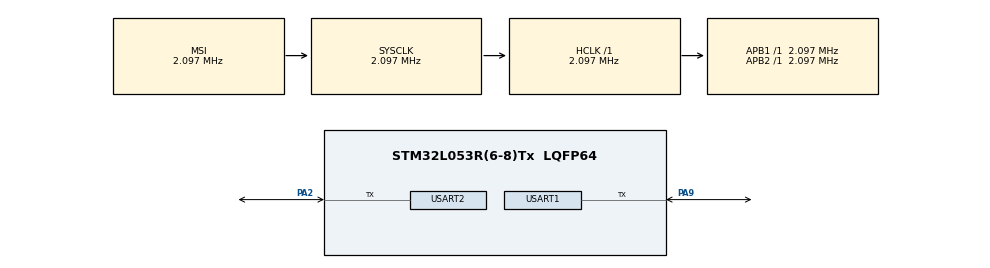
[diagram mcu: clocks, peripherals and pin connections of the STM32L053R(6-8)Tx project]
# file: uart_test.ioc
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Dma.Request0=USART1_TX
Dma.USART1_TX.0.Direction=DMA_MEMORY_TO_PERIPH
Dma.USART1_TX.0.Instance=DMA1_Channel2
Dma.USART1_TX.0.MemDataAlignment=DMA_MDATAALIGN_BYTE
Dma.USART1_TX.0.MemInc=DMA_MINC_ENABLE
Dma.USART1_TX.0.Mode=DMA_NORMAL
Dma.USART1_TX.0.PeriphDataAlignment=DMA_PDATAALIGN_BYTE
Dma.USART1_TX.0.PeriphInc=DMA_PINC_DISABLE
Dma.USART1_TX.0.Priority=DMA_PRIORITY_LOW
Mcu.Family=STM32L0
Mcu.Name=STM32L053R(6-8)Tx
Mcu.Package=LQFP64
NVIC.DMA1_Channel2_3_IRQn=true\:0\:0\:false\:false\:true
NVIC.USART1_IRQn=true\:0\:0\:false\:false\:true
PA2.Mode=Half_duplex(single_wire_mode)
PA2.Signal=USART2_TX
PA9.Mode=Half_duplex(single_wire_mode)
PA9.Signal=USART1_TX
ProjectManager.HeapSize=0x200
ProjectManager.StackSize=0x400
ProjectManager.TargetToolchain=SW4STM32
RCC.48MEnable=false
RCC.ADCEnable=false
RCC.AHBFreq_Value=2097000
RCC.APB1Freq_Value=2097000
RCC.APB1TimFreq_Value=2097000
RCC.APB2Freq_Value=2097000
RCC.APB2TimFreq_Value=2097000
RCC.ClockTypeHCLK=RCC_CLOCKTYPE_HCLK
RCC.ClockTypePCLK1=RCC_CLOCKTYPE_PCLK1
RCC.ClockTypePCLK2=RCC_CLOCKTYPE_PCLK2
RCC.ClockTypeSysClk=RCC_CLOCKTYPE_SYSCLK
RCC.EnableCSSLSE=false
RCC.EnableHSE=false
RCC.EnableHSELCDDevisor=false
RCC.EnableHSERTCDevisor=false
RCC.EnableLSE=false
RCC.EnableLSERTC=false
RCC.EnbaleCSS=false
RCC.HSE_VALUE=8000000
RCC.HSI16State=RCC_HSI_OFF
RCC.HSI16_VALUE=16000000
RCC.HSI48State=RCC_HSI48_OFF
RCC.HSI48_VALUE=48000000
RCC.HSI_VALUE=16000000
RCC.I2C1Enable=false
RCC.IWDGEnable=false
RCC.LCDEnable=false
RCC.LPTIMEnable=false
RCC.LPUARTEnable=false
RCC.LSE_VALUE=32768
RCC.LSIState=RCC_LSI_OFF
RCC.MCOEnable=false
RCC.MSI_VALUE=2097000
RCC.PLLSource=RCC_PLLSOURCE_HSI
RCC.PLLSourceVirtual=RCC_PLLSOURCE_HSI
RCC.PLLState=RCC_PLL_OFF
RCC.RCC_PERIPHCLK_USART1Var=RCC_PERIPHCLK_USART1
RCC.RCC_PERIPHCLK_USART2Var=RCC_PERIPHCLK_USART2
RCC.RNGEnable=false
RCC.RTCEnable=false
RCC.SYSCLKFreq_VALUE=2097000
RCC.USART1Enable=true
RCC.USART2Enable=true
RCC.USBEnable=false
RCC.VCOOutputFreq_Value=48000000
USART1.BaudRate=115200
USART1.OverrunDisableParam=UART_ADVFEATURE_OVERRUN_DISABLE
USART1.VirtualMode-Half_duplex(single_wire_mode)=VM_ASYNC
USART1.WordLength=WORDLENGTH_8B
USART2.VirtualMode-Half_duplex(single_wire_mode)=VM_ASYNC
board=uart_test

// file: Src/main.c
/**
  ******************************************************************************
  * File Name          : main.c
  * Description        : Main program body
  ******************************************************************************
  *
  * COPYRIGHT(c) 2017 STMicroelectronics
  *
  * Redistribution and use in source and binary forms, with or without modification,
  * are permitted provided that the following conditions are met:
  *   1. Redistributions of source code must retain the above copyright notice,
  *      this list of conditions and the following disclaimer.
  *   2. Redistributions in binary form must reproduce the above copyright notice,
  *      this list of conditions and the following disclaimer in the documentation
  *      and/or other materials provided with the distribution.
  *   3. Neither the name of STMicroelectronics nor the names of its contributors
  *      may be used to endorse or promote products derived from this software
  *      without specific prior written permission.
  *
  * THIS SOFTWARE IS PROVIDED BY THE COPYRIGHT HOLDERS AND CONTRIBUTORS "AS IS"
  * AND ANY EXPRESS OR IMPLIED WARRANTIES, INCLUDING, BUT NOT LIMITED TO, THE
  * IMPLIED WARRANTIES OF MERCHANTABILITY AND FITNESS FOR A PARTICULAR PURPOSE ARE
  * DISCLAIMED. IN NO EVENT SHALL THE COPYRIGHT HOLDER OR CONTRIBUTORS BE LIABLE
  * FOR ANY DIRECT, INDIRECT, INCIDENTAL, SPECIAL, EXEMPLARY, OR CONSEQUENTIAL
  * DAMAGES (INCLUDING, BUT NOT LIMITED TO, PROCUREMENT OF SUBSTITUTE GOODS OR
  * SERVICES; LOSS OF USE, DATA, OR PROFITS; OR BUSINESS INTERRUPTION) HOWEVER
  * CAUSED AND ON ANY THEORY OF LIABILITY, WHETHER IN CONTRACT, STRICT LIABILITY,
  * OR TORT (INCLUDING NEGLIGENCE OR OTHERWISE) ARISING IN ANY WAY OUT OF THE USE
  * OF THIS SOFTWARE, EVEN IF ADVISED OF THE POSSIBILITY OF SUCH DAMAGE.
  *
  ******************************************************************************
  */
#include "main.h"
#include "stm32l0xx_hal.h"

/* USER CODE BEGIN Includes */
#include "OwCompleteSearch.h"
#include "Callback.h"
#include "OneWireio.h"
#include "Search.h"
#include "OwVariable.h"
#include <stdlib.h>
/* USER CODE END Includes */

UART_HandleTypeDef huart1;
UART_HandleTypeDef huart2;
DMA_HandleTypeDef hdma_usart1_tx;

/* USER CODE BEGIN PV */
/* Private variables ---------------------------------------------------------*/
uint8_t send1 = 0xff;
uint8_t send0 = 0;
uint8_t uartRx;
uint8_t uartTempRx;
uint8_t pData;
uint8_t pDataTR[2] = {0xf0, 0x22};
int callBEn = 0;
uint8_t *romUIDprivate;
/* USER CODE END PV */

void SystemClock_Config(void);
void Error_Handler(void);
static void MX_GPIO_Init(void);
static void MX_DMA_Init(void);
static void MX_USART1_UART_Init(void);
static void MX_USART2_UART_Init(void);

/* USER CODE BEGIN PFP */
/* Private function prototypes -----------------------------------------------*/
HAL_StatusTypeDef HAL_HalfDuplex_EnableTxRx(UART_HandleTypeDef *huart);
/* USER CODE END PFP */

int main(void)
{

  /* MCU Configuration----------------------------------------------------------*/

  /* Reset of all peripherals, Initializes the Flash interface and the Systick. */
  HAL_Init();

  /* Configure the system clock */
  SystemClock_Config();

  /* Initialize all configured peripherals */
  MX_GPIO_Init();
  MX_DMA_Init();
  MX_USART1_UART_Init();
  MX_USART2_UART_Init();

  /* USER CODE BEGIN 2 */
  HAL_HalfDuplex_EnableTxRx(&huart1);
  owRomSearchInit();
  /* USER CODE END 2 */

  /* Infinite loop */
  while (1)
  {

  /* USER CODE BEGIN 3 */

    //callback flag is set to generate evt to send back to func in callbackList
	  if(callBEn){
		  Event evt;
		  evt.evtType = UART_RX_SUCCESS;
		  TxRxCpltEvData evData;
		  evData.uartRxVal = uartRxDataBuffer;
		  evt.data = &evData;
		  FuncP functPToCaller;
		  functPToCaller = getCurrentCallback((&list));
		  functPToCaller(&evt);
	  }

	  if(owSearchRomGetResult(romUIDprivate) == TRUE){
		  volatile int i = 0;
		  i++;
	  }

  }
  /* USER CODE END 3 */

}

/** System Clock Configuration
*/
void SystemClock_Config(void)
{

  RCC_OscInitTypeDef RCC_OscInitStruct;
  RCC_ClkInitTypeDef RCC_ClkInitStruct;
  RCC_PeriphCLKInitTypeDef PeriphClkInit;

    /**Configure the main internal regulator output voltage
    */
  __HAL_PWR_VOLTAGESCALING_CONFIG(PWR_REGULATOR_VOLTAGE_SCALE1);

    /**Initializes the CPU, AHB and APB busses clocks
    */
  RCC_OscInitStruct.OscillatorType = RCC_OSCILLATORTYPE_MSI;
  RCC_OscInitStruct.MSIState = RCC_MSI_ON;
  RCC_OscInitStruct.MSICalibrationValue = 0;
  RCC_OscInitStruct.MSIClockRange = RCC_MSIRANGE_5;
  RCC_OscInitStruct.PLL.PLLState = RCC_PLL_NONE;
  if (HAL_RCC_OscConfig(&RCC_OscInitStruct) != HAL_OK)
  {
    Error_Handler();
  }

    /**Initializes the CPU, AHB and APB busses clocks
    */
  RCC_ClkInitStruct.ClockType = RCC_CLOCKTYPE_HCLK|RCC_CLOCKTYPE_SYSCLK
                              |RCC_CLOCKTYPE_PCLK1|RCC_CLOCKTYPE_PCLK2;
  RCC_ClkInitStruct.SYSCLKSource = RCC_SYSCLKSOURCE_MSI;
  RCC_ClkInitStruct.AHBCLKDivider = RCC_SYSCLK_DIV1;
  RCC_ClkInitStruct.APB1CLKDivider = RCC_HCLK_DIV1;
  RCC_ClkInitStruct.APB2CLKDivider = RCC_HCLK_DIV1;

  if (HAL_RCC_ClockConfig(&RCC_ClkInitStruct, FLASH_LATENCY_0) != HAL_OK)
  {
    Error_Handler();
  }

  PeriphClkInit.PeriphClockSelection = RCC_PERIPHCLK_USART1|RCC_PERIPHCLK_USART2;
  PeriphClkInit.Usart1ClockSelection = RCC_USART1CLKSOURCE_PCLK2;
  PeriphClkInit.Usart2ClockSelection = RCC_USART2CLKSOURCE_PCLK1;
  if (HAL_RCCEx_PeriphCLKConfig(&PeriphClkInit) != HAL_OK)
  {
    Error_Handler();
  }

    /**Configure the Systick interrupt time
    */
  HAL_SYSTICK_Config(HAL_RCC_GetHCLKFreq()/1000);

    /**Configure the Systick
    */
  HAL_SYSTICK_CLKSourceConfig(SYSTICK_CLKSOURCE_HCLK);

  /* SysTick_IRQn interrupt configuration */
  HAL_NVIC_SetPriority(SysTick_IRQn, 0, 0);
}

/* USART1 init function */
static void MX_USART1_UART_Init(void)
{

  huart1.Instance = USART1;
  huart1.Init.BaudRate = 115200;
  huart1.Init.WordLength = UART_WORDLENGTH_8B;
  huart1.Init.StopBits = UART_STOPBITS_1;
  huart1.Init.Parity = UART_PARITY_NONE;
  huart1.Init.Mode = UART_MODE_TX_RX;
  huart1.Init.HwFlowCtl = UART_HWCONTROL_NONE;
  huart1.Init.OverSampling = UART_OVERSAMPLING_16;
  huart1.Init.OneBitSampling = UART_ONE_BIT_SAMPLE_DISABLE;
  huart1.AdvancedInit.AdvFeatureInit = UART_ADVFEATURE_RXOVERRUNDISABLE_INIT;
  huart1.AdvancedInit.OverrunDisable = UART_ADVFEATURE_OVERRUN_DISABLE;
  if (HAL_HalfDuplex_Init(&huart1) != HAL_OK)
  {
    Error_Handler();
  }

}

/* USART2 init function */
static void MX_USART2_UART_Init(void)
{

  huart2.Instance = USART2;
  huart2.Init.BaudRate = 115200;
  huart2.Init.WordLength = UART_WORDLENGTH_7B;
  huart2.Init.StopBits = UART_STOPBITS_1;
  huart2.Init.Parity = UART_PARITY_NONE;
  huart2.Init.Mode = UART_MODE_TX_RX;
  huart2.Init.HwFlowCtl = UART_HWCONTROL_NONE;
  huart2.Init.OverSampling = UART_OVERSAMPLING_16;
  huart2.Init.OneBitSampling = UART_ONE_BIT_SAMPLE_DISABLE;
  huart2.AdvancedInit.AdvFeatureInit = UART_ADVFEATURE_NO_INIT;
  if (HAL_HalfDuplex_Init(&huart2) != HAL_OK)
  {
    Error_Handler();
  }

}

static void MX_DMA_Init(void)
{
  /* DMA controller clock enable */
  __HAL_RCC_DMA1_CLK_ENABLE();

  /* DMA interrupt init */
  /* DMA1_Channel2_3_IRQn interrupt configuration */
  HAL_NVIC_SetPriority(DMA1_Channel2_3_IRQn, 0, 0);
  HAL_NVIC_EnableIRQ(DMA1_Channel2_3_IRQn);

}

/** Pinout Configuration
*/
static void MX_GPIO_Init(void)
{

  /* GPIO Ports Clock Enable */
  __HAL_RCC_GPIOA_CLK_ENABLE();

}

/* USER CODE BEGIN 4 */
void owRomSearchInit(){
  setUartBaudRate(9600);
  romUIDprivate = (uint8_t*)malloc(8);
  uartRxDataBuffer = (uint8_t*)malloc(2);
  Event evt;
  evt.evtType = START_ROM_SEARCH;
  doRomSearch(&evt);
}
int owSearchRomGetResult(uint8_t *romUid){
	if(searchCpltF == 1){
		searchCpltF = 0;
		*romUid = *doRomSearchPrivate.romVal;
		return TRUE;
	}
	return FALSE;
}
HAL_StatusTypeDef HAL_HalfDuplex_EnableTxRx(UART_HandleTypeDef *huart)
{
  /* Process Locked */
  __HAL_LOCK(huart);
  huart->gState = HAL_UART_STATE_BUSY;

  /* Enable the USART's receive interface by setting the RE bit in the USART CR1 register */
  SET_BIT(huart->Instance->CR1, USART_CR1_TE | USART_CR1_RE);

  huart->gState = HAL_UART_STATE_READY;
  /* Process Unlocked */
  __HAL_UNLOCK(huart);

  return HAL_OK;
}

void write(uint8_t byte){
	if(byte > 0)
		HAL_UART_Transmit(&huart1, &send1, 1, 500);
	else
		HAL_UART_Transmit(&huart1, &send0, 1, 500);
}

uint8_t Read(){
	HAL_UART_Transmit(&huart1, &send1, 1, 50);
	HAL_UART_Receive(&huart1, &owRxCallBackData, 1, 50);
	volatile int i = 0;
	i++;
	if(owRxCallBackData == 0xff)
		return 1;
	else
		return 0;
}

void writeSendArray(uint8_t* data, int length){
  int i;
  for(i =0;i<length;i++){
    write(*(data+i));
  }
}

void uartTxOw(uint8_t* data, int length){
  int i;
  for(i =0;i<length;i++){
    write(*(data+i));
  }
}

void owSetUpRxIT(uint8_t* data, int bitLength){
	HAL_UART_Receive_IT(&huart1, data, bitLength);
}

void owUartTxDma(uint8_t data){
	//HAL_UART_AbortTransmit(&huart1);
	while(HAL_UART_Transmit_DMA(&huart1, &data, 1) == HAL_BUSY){
		volatile int i = 0;
		i++;
	}
}

void owUartTxDma2(uint8_t data){
	uint8_t *ptr = (uint8_t*)malloc(2);
	*(ptr) = data;
	*(ptr+1) = data;
	//HAL_UART_AbortTransmit(&huart1);
	while(HAL_UART_Transmit_DMA(&huart1, ptr, 1) == HAL_BUSY){
		volatile int i = 0;
		i++;
	}
}

void owUartTx(uint8_t data){
	if(HAL_UART_Transmit(&huart1, &data, 1, 50)!=HAL_OK){
		volatile int i = 0;
			i++;
	}

	volatile int j = 0;
	j++;
}
uint8_t owUartRx(){
	HAL_UART_Receive(&huart1, &uartTempRx, 1, 50);
	return uartTempRx;
}

void HAL_UART_TxCpltCallback(UART_HandleTypeDef *huart){
	volatile int i =0;
	i++;

}

void HAL_UART_RxCpltCallback(UART_HandleTypeDef *huart){
  //TODO find respective callback function
  callBEn = 1;
}

int isUartFrameError(){
	//TODO: future implementation here
	return 0;
}

void setUartBaudRate(int baudRate){
	huart1.Init.BaudRate = baudRate;
	if (HAL_HalfDuplex_Init(&huart1) != HAL_OK)
	{
		Error_Handler();
	}
}
void resetUart(int baudRate){
	MX_USART1_UART_Init();
	huart1.Init.BaudRate = baudRate;
	if (HAL_HalfDuplex_Init(&huart1) != HAL_OK)
	{
		Error_Handler();
	}
}

void uartDelay(int delay){
	HAL_Delay(delay);
}

void systemError(EventType evtType){
	while(1){
		//TODO do something instead of while loop
	}
}
/* USER CODE END 4 */

void Error_Handler(void)
{
  while(1)
  {
  }
}

/************************ (C) COPYRIGHT STMicroelectronics *****END OF FILE****/
